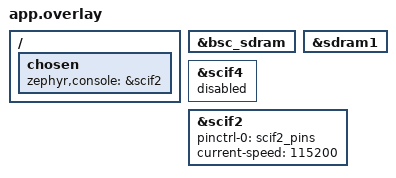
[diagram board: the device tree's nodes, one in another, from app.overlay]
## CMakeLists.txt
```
# Copyright (c) 2023 EPAM Systems
# SPDX-License-Identifier: Apache-2.0

cmake_minimum_required(VERSION 3.20.0)
find_package(Zephyr REQUIRED HINTS $ENV{ZEPHYR_BASE})

project(bsc_rz_a2m)

target_sources(app PRIVATE src/main.c)
```

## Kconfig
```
# Copyright (c) 2023 EPAM Systems
# SPDX-License-Identifier: Apache-2.0

mainmenu "BSC RZ/A2M Test"

source "Kconfig.zephyr"
```

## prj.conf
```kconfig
CONFIG_ZTEST=y
CONFIG_ZTEST_NEW_API=y
# Increase number of L2 tables because initial value
# is not enough to map external space
CONFIG_ARM_MMU_NUM_L2_TABLES=128
```

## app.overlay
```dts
/*
 * Copyright (c) 2023 EPAM Systems
 * SPDX-License-Identifier: Apache-2.0
 */

/ {
	chosen {
		zephyr,console = &scif2;
	};
};

&bsc_sdram {
	status = "okay";
};

&sdram1 {
	status = "okay";
};

&scif4 {
	status = "disabled";
};

&scif2 {
	pinctrl-0 = <&scif2_pins>;
	pinctrl-names = "default";
	current-speed = <115200>;
	status = "okay";
};
```

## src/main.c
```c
/*
 * Copyright (c) 2023 EPAM Systems
 *
 * SPDX-License-Identifier: Apache-2.0
 */

#include <zephyr/ztest.h>

#define TEST_MEM_VALUE 0xdeadbeef

ZTEST(bsc_rza2_suite, test_mem_set)
{
	/* External SDRAM connected to the subboard should be initialized on start */
	long *p = (long *)0x0C000000;
	*p = TEST_MEM_VALUE;
	zassert_equal(*p, TEST_MEM_VALUE, "Unable to set value to the external SDRAM address");
}

ZTEST_SUITE(bsc_rza2_suite, NULL, NULL, NULL, NULL, NULL);
```
